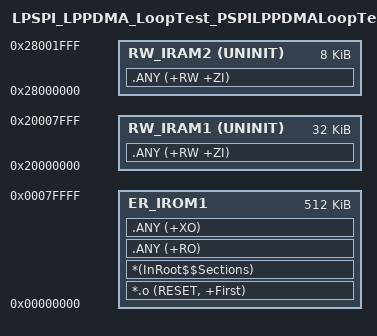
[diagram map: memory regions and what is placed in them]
; ***********************************************************************
; *** Scatter-Loading Description File generated by uv2csolution ***
; ***********************************************************************

LR_IROM1 0x00000000 0x00080000 {    ; load region size_region
  ER_IROM1 0x00000000 0x00080000 {  ; load address = execution address
   *.o (RESET, +First)
   *(InRoot$$Sections)
   .ANY (+RO)
   .ANY (+XO)
  }
  RW_IRAM1 0x20000000 UNINIT 0x00008000 {  ; RW data
   .ANY (+RW +ZI)
  }
  RW_IRAM2 0x28000000 UNINIT 0x00002000 {
   .ANY (+RW +ZI)
  }
}

